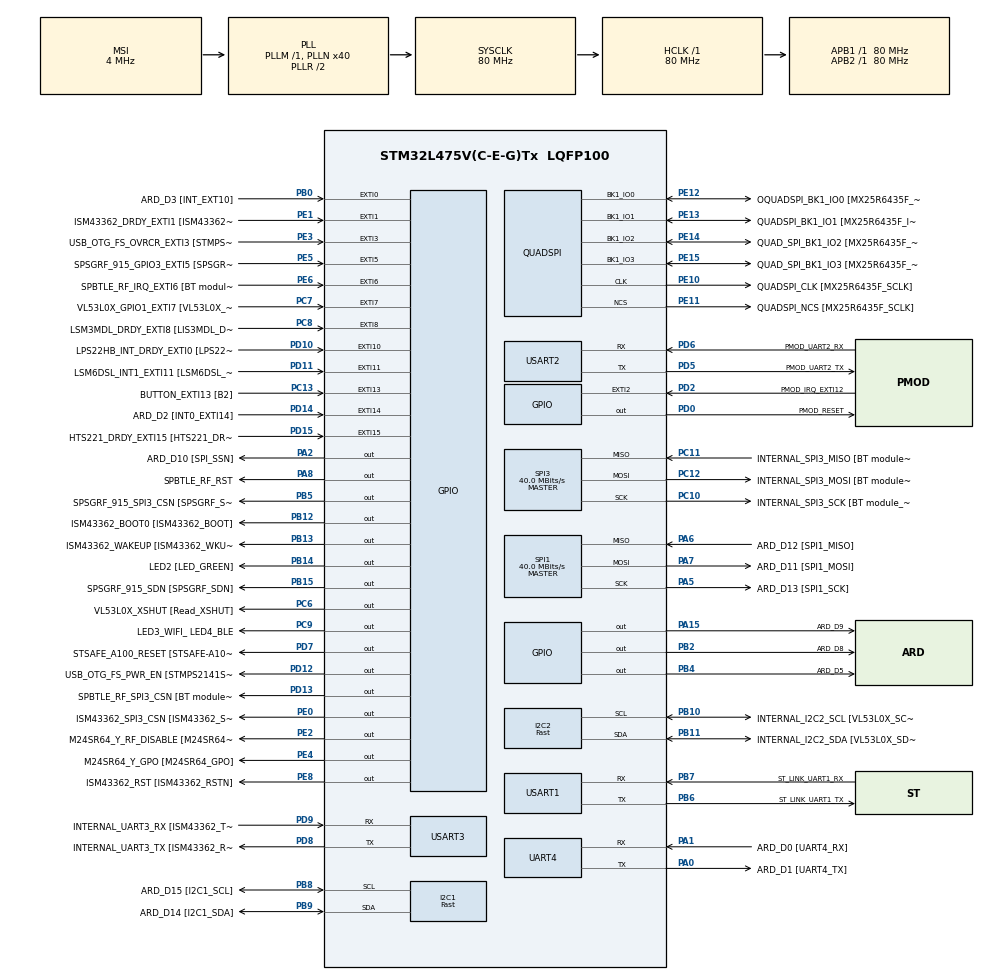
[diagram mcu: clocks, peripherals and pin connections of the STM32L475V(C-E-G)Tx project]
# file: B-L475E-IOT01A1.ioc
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PD12.GPIO_Label=USB_OTG_FS_PWR_EN [STMPS2141STR_EN]
SPI3.Direction=SPI_DIRECTION_2LINES
SPI3.VirtualType=VM_MASTER
I2C1.I2C_Speed_Mode=I2C_Fast
SPI1.VirtualType=VM_MASTER
PB10.Mode=I2C
PC12.Signal=SPI3_MOSI
PB14.GPIO_Label=LED2 [LED_GREEN]
PC6.GPIO_Label=VL53L0X_XSHUT [Read_XSHUT]
PA6.GPIO_Label=ARD_D12 [SPI1_MISO]
PB6.GPIO_Label=ST_LINK_UART1_TX
PA15\ (JTDI).Signal=GPIO_Output
PB13.Signal=GPIO_Output
PD6.GPIO_Label=PMOD_UART2_RX
PE6.GPIO_Label=SPBTLE_RF_IRQ_EXTI6 [BT module_SPI_IRQ]
RCC.SYSCLKSource=RCC_SYSCLKSOURCE_PLLCLK
SH.ADCx_IN16.0=ADC1_IN16
USART3.VirtualMode-Asynchronous=VM_ASYNC
PA14\ (JTCK-SWCLK).Signal=SYS_JTCK-SWCLK
NVIC.EXTI1_IRQn=true\:5\:0\:false\:true\:true\:1\:true\:true\:true
SPI1.Direction=SPI_DIRECTION_2LINES
PD4.Signal=USART2_RTS
I2C2.I2C_Speed_Mode=I2C_Fast
RCC.APB2TimFreq_Value=80000000
PB6.Signal=USART1_TX
PC7.Signal=GPXTI7
PB6.Mode=Asynchronous
SPI1.CalculateBaudRate=40.0 MBits/s
PC3.Signal=ADCx_IN4
PD0.Signal=GPIO_Output
PD8.Signal=USART3_TX
PE5.Signal=GPXTI5
PE1.Signal=GPXTI1
NVIC.EXTI15_10_IRQn=true\:5\:0\:false\:false\:true\:true\:true\:true
PB2.Signal=GPIO_Output
PD1.GPIO_Label=PMOD_SPI2_SCK
PB12.GPIO_Label=ISM43362_BOOT0 [ISM43362_BOOT]
PC4.GPIO_Label=ARD_A1 [ADC]
PE9.Signal=S_CKOUTDFSDM1
PB1.GPIO_Label=ARD_D6 [ADC1_IN6]
PE4.GPIO_Label=M24SR64_Y_GPO [M24SR64_GPO]
PA0.Mode=Asynchronous
PE2.Signal=GPIO_Output
PA8.Signal=GPIO_Output
PE13.Mode=Single Bank
PE10.Signal=QUADSPI_CLK
PA0.Signal=UART4_TX
Mcu.Package=LQFP100
PB9.Signal=I2C1_SDA
PB1.Signal=ADCx_IN16
NVIC.TimeBase=TIM1_TRG_COM_TIM17_IRQn
SPI3.Mode=SPI_MODE_MASTER
SH.ADCx_IN14.0=ADC1_IN14
PD12.Signal=GPIO_Output
NVIC.TimeBaseIP=TIM17
PA10.Signal=USB_OTG_FS_ID
PE12.GPIO_Label=OQUADSPI_BK1_IO0 [MX25R6435F_IO0]
PC11.Mode=Full_Duplex_Master
SH.ADCx_IN9.0=ADC1_IN9
RCC.APB1TimFreq_Value=80000000
PA13\ (JTMS-SWDIO).Signal=SYS_JTMS-SWDIO
PE10.GPIO_Label=QUADSPI_CLK [MX25R6435F_SCLK]
PA4.GPIO_Label=ARD_D7
PD15.Signal=GPXTI15
NVIC.UART4_IRQn=true\:5\:0\:false\:false\:true\:true\:true\:true
PA5.Mode=Full_Duplex_Master
PE12.Mode=Single Bank
NVIC.QUADSPI_IRQn=true\:5\:0\:false\:false\:true\:true\:true\:true
FREERTOS.Tasks01=defaultTask,24,128,StartDefaultTask,Default,NULL,Dynamic,NULL,NULL;App_Main_Task,40,256,APP_Main_Task,Default,NULL,Dynamic,NULL,NULL;App_Drv_Main_Ta,48,256,App_Drv_Main_Task,Default,NULL,Dynamic,NULL,NULL
PD9.GPIO_Label=INTERNAL_UART3_RX [ISM43362_TX]
VP_SYS_VS_tim17.Mode=TIM17
PA9.GPIO_Label=USB_OTG_FS_VBUS [STMPS2141STR_OUT]
PC13.Signal=GPXTI13
PD3.Signal=USART2_CTS
PC6.Signal=GPIO_Output
PE10.Mode=Single Bank
PC2.Signal=ADCx_IN3
PB11.GPIO_Label=INTERNAL_I2C2_SDA [VL53L0X_SDA]
PD7.Signal=GPIO_Output
PD1.Signal=SPI2_SCK
PA11.GPIO_Label=USB_OTG_FS_DM
PC0.Signal=ADCx_IN1
PD6.Mode=Asynchronous
PD10.Signal=GPXTI10
PB8.GPIO_Label=ARD_D15 [I2C1_SCL]
PA8.GPIO_Label=SPBTLE_RF_RST
PB11.Mode=I2C
PE8.GPIO_Label=ISM43362_RST [ISM43362_RSTN]
PA9.Signal=USB_OTG_FS_VBUS
I2C1.Timing=0x00702991
NVIC.I2C2_ER_IRQn=true\:5\:0\:false\:false\:true\:true\:true\:true
PE9.GPIO_Label=DFSDM1_CKOUT [MP34DT01_CLK]
PD8.Mode=Asynchronous
PB10.Signal=I2C2_SCL
PB14.Signal=GPIO_Output
PA5.Signal=SPI1_SCK
PC12.Mode=Full_Duplex_Master
PE1.GPIO_Label=ISM43362_DRDY_EXTI1 [ISM43362_DATARDY]
NVIC.SPI1_IRQn=true\:5\:0\:false\:false\:true\:true\:true\:true
PA1.Mode=Asynchronous
PE14.Signal=QUADSPI_BK1_IO2
PE15.Signal=QUADSPI_BK1_IO3
PB15.GPIO_Label=SPSGRF_915_SDN [SPSGRF_SDN]
PE8.Signal=GPIO_Output
SPI1.Mode=SPI_MODE_MASTER
PA1.GPIO_Label=ARD_D0 [UART4_RX]
SH.ADCx_IN4.0=ADC1_IN4
PC7.GPIO_Label=VL53L0X_GPIO1_EXTI7 [VL53L0X_GPIO1]
PA13\ (JTMS-SWDIO).Mode=Serial_Wire
PA4.Signal=ADCx_IN9
PB5.Signal=GPIO_Output
PE13.GPIO_Label=QUADSPI_BK1_IO1 [MX25R6435F_IO1]
PA5.GPIO_Label=ARD_D13 [SPI1_SCK]
PD11.Signal=GPXTI11
PE5.GPIO_Label=SPSGRF_915_GPIO3_EXTI5 [SPSGRF_GPIO_3]
PC12.GPIO_Label=INTERNAL_SPI3_MOSI [BT module_SPI_MOSI] [ISM43362_MOSI]
PA11.Signal=USB_OTG_FS_DM
ProjectManager.HeapSize=0x1000
NVIC.PriorityGroup=NVIC_PRIORITYGROUP_4
PB8.Mode=I2C
PE3.Signal=GPXTI3
PC3.GPIO_Label=ARD_A2 [ADC]
PB4\ (NJTRST).GPIO_Label=ARD_D5
PD2.Signal=GPXTI2
PB0.Signal=GPXTI0
PC1.Signal=ADCx_IN2
PD2.GPIO_Label=PMOD_IRQ_EXTI12
PE15.Mode=Single Bank
Mcu.Family=STM32L4
NVIC.USART3_IRQn=true\:5\:0\:false\:false\:true\:true\:true\:true
PA6.Mode=Full_Duplex_Master
RCC.CortexFreq_Value=80000000
PE11.GPIO_Label=QUADSPI_NCS [MX25R6435F_SCLK]
SH.ADCx_IN2.0=ADC1_IN2
PC10.Signal=SPI3_SCK
I2C2.Timing=0x00702991
PA0.GPIO_Label=ARD_D1 [UART4_TX]
PC0.GPIO_Label=ARD_A5 [ADC]
PD0.GPIO_Label=PMOD_RESET
PB0.GPIO_Label=ARD_D3 [INT_EXT10]
PC13.GPIO_Label=BUTTON_EXTI13 [B2]
PB13.GPIO_Label=ISM43362_WAKEUP [ISM43362_WKUP]
PB11.Signal=I2C2_SDA
PB15.Signal=GPIO_Output
PD9.Mode=Asynchronous
ProjectManager.StackSize=0x1000
PB3\ (JTDO-TRACESWO).Signal=SYS_JTDO-SWO
VP_FREERTOS_VS_CMSIS_V2.Mode=CMSIS_V2
PD13.Signal=GPIO_Output
PA12.Signal=USB_OTG_FS_DP
PE11.Mode=Single Bank
PD11.GPIO_Label=LSM6DSL_INT1_EXTI11 [LSM6DSL_INT1]
RCC.HCLKFreq_Value=80000000
SH.ADCx_IN3.0=ADC1_IN3
PB5.PinState=GPIO_PIN_SET
RCC.AHBFreq_Value=80000000
PD5.Mode=Asynchronous
RCC.HSE_VALUE=8000000
USART2.VirtualMode-Asynchronous=VM_ASYNC
NVIC.TIM1_TRG_COM_TIM17_IRQn=true\:0\:0\:false\:false\:true\:false\:false\:true
PE13.Signal=QUADSPI_BK1_IO1
PC11.GPIO_Label=INTERNAL_SPI3_MISO [BT module_SPI_MISO] [ISM43362_MISO]
PA10.GPIO_Label=USB_OTG_FS_ID
PB7.Signal=USART1_RX
PE4.Signal=GPIO_Output
PD7.GPIO_Label=STSAFE_A100_RESET [STSAFE-A100_RESET]
PB7.GPIO_Label=ST_LINK_UART1_RX
PD13.GPIO_Label=SPBTLE_RF_SPI3_CSN [BT module_SPI_CS]
PA6.Signal=SPI1_MISO
PD5.GPIO_Label=PMOD_UART2_TX
PA2.GPIO_Label=ARD_D10 [SPI_SSN]
NVIC.SPI3_IRQn=true\:5\:0\:false\:false\:true\:true\:true\:true
PE0.GPIO_Label=ISM43362_SPI3_CSN [ISM43362_SSN]
SH.ADCx_IN1.0=ADC1_IN1
PB5.GPIO_Label=SPSGRF_915_SPI3_CSN [SPSGRF_SPI_CS]
PC5.Signal=ADCx_IN14
PD3.GPIO_Label=PMOD_UART2_CTS
PE7.Signal=S_DATAIN2DFSDM1
PD6.Signal=USART2_RX
PE2.GPIO_Label=M24SR64_Y_RF_DISABLE [M24SR64_RFDIS]
PC2.GPIO_Label=ARD_A3 [ADC]
RCC.PLLSAI1N=16
PA3.Signal=S_TIM2_CH4
RCC.MSI_VALUE=4000000
PA14\ (JTCK-SWCLK).Mode=Serial_Wire
SH.ADCx_IN13.0=ADC1_IN13
PD15.GPIO_Label=HTS221_DRDY_EXTI15 [HTS221_DRDY]
PA7.Mode=Full_Duplex_Master
PB9.GPIO_Label=ARD_D14 [I2C1_SDA]
PC10.GPIO_Label=INTERNAL_SPI3_SCK [BT module_SPI_SCLK] [ISM43362_SCK]
PC9.GPIO_Label=LED3_WIFI_ LED4_BLE
PC11.Signal=SPI3_MISO
PC8.Signal=GPXTI8
PC4.Signal=ADCx_IN13
PC10.Mode=Full_Duplex_Master
SH.S_DATAIN2DFSDM1.0=DFSDM1_DATIN2
PE14.GPIO_Label=QUAD_SPI_BK1_IO2 [MX25R6435F_IO2]
PC15-OSC32_OUT\ (PC15).Signal=RCC_OSC32_OUT
PD9.Signal=USART3_RX
PD5.Signal=USART2_TX
PA14\ (JTCK-SWCLK).GPIO_Label=SYS_JTCK_SWCLK
PB3\ (JTDO-TRACESWO).GPIO_Label=SYS_JTD0_SWO
VP_RNG_VS_RNG.Mode=RNG_Activate
NVIC.USART2_IRQn=true\:5\:0\:false\:false\:true\:true\:true\:true
PA12.GPIO_Label=USB_OTG_FS_DP
PD8.GPIO_Label=INTERNAL_UART3_TX [ISM43362_RX]
PC8.GPIO_Label=LSM3MDL_DRDY_EXTI8 [LIS3MDL_DRDY]
USART1.VirtualMode-Asynchronous=VM_ASYNC
PE0.PinState=GPIO_PIN_SET
PE15.GPIO_Label=QUAD_SPI_BK1_IO3 [MX25R6435F_IO3]
ProjectManager.TargetToolchain=STM32CubeIDE
PB10.GPIO_Label=INTERNAL_I2C2_SCL [VL53L0X_SCL]
PB9.Mode=I2C
RCC.USBFreq_Value=32000000
PD10.GPIO_Label=LPS22HB_INT_DRDY_EXTI0 [LPS22HB_INT_DRDY] 
PE11.Signal=QUADSPI_NCS
RCC.LSE_VALUE=32768
PA1.Signal=UART4_RX
board=B-L475E-IOT01A1
RCC.VCOOutputFreq_Value=160000000
RCC.APB2Freq_Value=80000000
SPI3.CalculateBaudRate=40.0 MBits/s
PA13\ (JTMS-SWDIO).GPIO_Label=SYS_JTMS_SWDIO
PD4.GPIO_Label=PMOD_UART2_RTS
PE14.Mode=Single Bank
SH.S_CKOUTDFSDM1.0=DFSDM1_CKOUT
RCC.ADCFreq_Value=32000000
PC1.GPIO_Label=ARD_A4 [ADC]
PD14.GPIO_Label=ARD_D2 [INT0_EXTI14]
PE6.Signal=GPXTI6
PA15\ (JTDI).GPIO_Label=ARD_D9
Mcu.Name=STM32L475V(C-E-G)Tx
PE0.Signal=GPIO_Output
PE7.GPIO_Label=DFSDM1_DATIN2 [MP34DT01_DOUT]
PE12.Signal=QUADSPI_BK1_IO0
PA2.Signal=GPIO_Output
PD14.Signal=GPXTI14
RCC.SYSCLKFreq_VALUE=80000000
PA7.GPIO_Label=ARD_D11 [SPI1_MOSI]
PC13.GPIO_ModeDefaultEXTI=GPIO_MODE_IT_FALLING
PC5.GPIO_Label=ARD_A0 [ADC]
PC14-OSC32_IN\ (PC14).Signal=RCC_OSC32_IN
PB7.Mode=Asynchronous
NVIC.EXTI9_5_IRQn=true\:5\:0\:false\:false\:true\:true\:true\:true
PB2.GPIO_Label=ARD_D8
SH.S_TIM2_CH4.0=TIM2_CH4
NVIC.I2C2_EV_IRQn=true\:5\:0\:false\:false\:true\:true\:true\:true
RCC.HSI_VALUE=16000000
RCC.PLLN=40
PB8.Signal=I2C1_SCL
PE3.GPIO_Label=USB_OTG_FS_OVRCR_EXTI3 [STMPS2141STR_FAULT]
PC9.Signal=GPIO_Output
PD13.PinState=GPIO_PIN_SET
RCC.APB1Freq_Value=80000000
PB12.Signal=GPIO_Output
PA3.GPIO_Label=ARD_D4
PA7.Signal=SPI1_MOSI
PB4\ (NJTRST).Signal=GPIO_Output

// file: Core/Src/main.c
/* USER CODE BEGIN Header */
/**
  ******************************************************************************
  * @file           : main.c
  * @brief          : Main program body
  ******************************************************************************
  * @attention
  *
  * <h2><center>&copy; Copyright (c) 2021 STMicroelectronics.
  * All rights reserved.</center></h2>
  *
  * This software component is licensed by ST under BSD 3-Clause license,
  * the "License"; You may not use this file except in compliance with the
  * License. You may obtain a copy of the License at:
  *                        opensource.org/licenses/BSD-3-Clause
  *
  ******************************************************************************
  */
/* USER CODE END Header */
#include "main.h"
#include "cmsis_os.h"

/* USER CODE BEGIN Includes */
#include "APP/app_main.h"

/* USER CODE END Includes */

I2C_HandleTypeDef hi2c1;
I2C_HandleTypeDef hi2c2;

QSPI_HandleTypeDef hqspi;

RNG_HandleTypeDef hrng;

SPI_HandleTypeDef hspi1;
SPI_HandleTypeDef hspi3;

UART_HandleTypeDef huart4;
UART_HandleTypeDef huart1;
UART_HandleTypeDef huart2;
UART_HandleTypeDef huart3;

/* Definitions for defaultTask */
osThreadId_t defaultTaskHandle;
const osThreadAttr_t defaultTask_attributes = {
  .name = "defaultTask",
  .stack_size = 128 * 4,
  .priority = (osPriority_t) osPriorityNormal,
};
/* Definitions for App_Main_Task */
osThreadId_t App_Main_TaskHandle;
const osThreadAttr_t App_Main_Task_attributes = {
  .name = "App_Main_Task",
  .stack_size = 2048,
  .priority = (osPriority_t) osPriorityHigh,
};
/* Definitions for App_Drv_Main_Ta */
osThreadId_t App_Drv_Main_TaHandle;
const osThreadAttr_t App_Drv_Main_Ta_attributes = {
  .name = "App_Drv_Main_Ta",
  .stack_size = 256 * 4,
  .priority = (osPriority_t) osPriorityRealtime,
};
/* USER CODE BEGIN PV */

#if 0
osThreadId_t App_Main_Proc_TaskHandle;
const osThreadAttr_t App_Main_Proc_Task_attributes = {
  .name = "App Main Proc Task",
  .stack_size = 512 * 4,
  .priority = (osPriority_t) osPriorityHigh,
};
#endif

/* USER CODE END PV */

void SystemClock_Config(void);
static void MX_GPIO_Init(void);
static void MX_RNG_Init(void);
static void MX_I2C2_Init(void);
static void MX_QUADSPI_Init(void);
static void MX_SPI1_Init(void);
static void MX_SPI3_Init(void);
static void MX_UART4_Init(void);
static void MX_USART1_UART_Init(void);
static void MX_USART2_UART_Init(void);
static void MX_USART3_UART_Init(void);
static void MX_I2C1_Init(void);
void StartDefaultTask(void *argument);
void APP_Main_Task(void *argument);
void App_Drv_Main_Task(void *argument);

static void MX_NVIC_Init(void);

int main(void)
{

  /* MCU Configuration--------------------------------------------------------*/

  /* Reset of all peripherals, Initializes the Flash interface and the Systick. */
  HAL_Init();

  /* Configure the system clock */
  SystemClock_Config();

  /* Initialize all configured peripherals */
  MX_GPIO_Init();
  MX_RNG_Init();
  MX_I2C2_Init();
  MX_QUADSPI_Init();
  MX_SPI1_Init();
  MX_SPI3_Init();
  MX_UART4_Init();
  MX_USART1_UART_Init();
  MX_USART2_UART_Init();
  MX_USART3_UART_Init();
  MX_I2C1_Init();

  /* Initialize interrupts */
  MX_NVIC_Init();
  /* USER CODE BEGIN 2 */

  APP_BSP_Init();
  APP_Init();

  /* USER CODE END 2 */

  /* Init scheduler */
  osKernelInitialize();

  /* Create the thread(s) */
  /* creation of defaultTask */
  defaultTaskHandle = osThreadNew(StartDefaultTask, NULL, &defaultTask_attributes);

  /* creation of App_Main_Task */
  App_Main_TaskHandle = osThreadNew(APP_Main_Task, NULL, &App_Main_Task_attributes);

  /* creation of App_Drv_Main_Ta */
  App_Drv_Main_TaHandle = osThreadNew(App_Drv_Main_Task, NULL, &App_Drv_Main_Ta_attributes);

  /* USER CODE BEGIN RTOS_THREADS */
  /* add threads, ... */

  // APP Main Proc Task Create
  // App_Main_Proc_TaskHandle = osThreadNew(APP_Main_Proc_Task, NULL, &App_Main_Proc_Task_attributes);

  /* USER CODE END RTOS_THREADS */

  /* Start scheduler */
  osKernelStart();

  /* We should never get here as control is now taken by the scheduler */
  /* Infinite loop */
  while (1)
  {

  }
}

void SystemClock_Config(void)
{
  RCC_OscInitTypeDef RCC_OscInitStruct = {0};
  RCC_ClkInitTypeDef RCC_ClkInitStruct = {0};
  RCC_PeriphCLKInitTypeDef PeriphClkInit = {0};

  /** Initializes the RCC Oscillators according to the specified parameters
  * in the RCC_OscInitTypeDef structure.
  */
  RCC_OscInitStruct.OscillatorType = RCC_OSCILLATORTYPE_MSI;
  RCC_OscInitStruct.MSIState = RCC_MSI_ON;
  RCC_OscInitStruct.MSICalibrationValue = 0;
  RCC_OscInitStruct.MSIClockRange = RCC_MSIRANGE_6;
  RCC_OscInitStruct.PLL.PLLState = RCC_PLL_ON;
  RCC_OscInitStruct.PLL.PLLSource = RCC_PLLSOURCE_MSI;
  RCC_OscInitStruct.PLL.PLLM = 1;
  RCC_OscInitStruct.PLL.PLLN = 40;
  RCC_OscInitStruct.PLL.PLLP = RCC_PLLP_DIV7;
  RCC_OscInitStruct.PLL.PLLQ = RCC_PLLQ_DIV2;
  RCC_OscInitStruct.PLL.PLLR = RCC_PLLR_DIV2;
  if (HAL_RCC_OscConfig(&RCC_OscInitStruct) != HAL_OK)
  {
    Error_Handler();
  }
  /** Initializes the CPU, AHB and APB buses clocks
  */
  RCC_ClkInitStruct.ClockType = RCC_CLOCKTYPE_HCLK|RCC_CLOCKTYPE_SYSCLK
                              |RCC_CLOCKTYPE_PCLK1|RCC_CLOCKTYPE_PCLK2;
  RCC_ClkInitStruct.SYSCLKSource = RCC_SYSCLKSOURCE_PLLCLK;
  RCC_ClkInitStruct.AHBCLKDivider = RCC_SYSCLK_DIV1;
  RCC_ClkInitStruct.APB1CLKDivider = RCC_HCLK_DIV1;
  RCC_ClkInitStruct.APB2CLKDivider = RCC_HCLK_DIV1;

  if (HAL_RCC_ClockConfig(&RCC_ClkInitStruct, FLASH_LATENCY_4) != HAL_OK)
  {
    Error_Handler();
  }
  PeriphClkInit.PeriphClockSelection = RCC_PERIPHCLK_USART1|RCC_PERIPHCLK_USART2
                              |RCC_PERIPHCLK_USART3|RCC_PERIPHCLK_UART4
                              |RCC_PERIPHCLK_I2C1|RCC_PERIPHCLK_I2C2
                              |RCC_PERIPHCLK_RNG;
  PeriphClkInit.Usart1ClockSelection = RCC_USART1CLKSOURCE_PCLK2;
  PeriphClkInit.Usart2ClockSelection = RCC_USART2CLKSOURCE_PCLK1;
  PeriphClkInit.Usart3ClockSelection = RCC_USART3CLKSOURCE_PCLK1;
  PeriphClkInit.Uart4ClockSelection = RCC_UART4CLKSOURCE_PCLK1;
  PeriphClkInit.I2c1ClockSelection = RCC_I2C1CLKSOURCE_PCLK1;
  PeriphClkInit.I2c2ClockSelection = RCC_I2C2CLKSOURCE_PCLK1;
  PeriphClkInit.RngClockSelection = RCC_RNGCLKSOURCE_PLLSAI1;
  PeriphClkInit.PLLSAI1.PLLSAI1Source = RCC_PLLSOURCE_MSI;
  PeriphClkInit.PLLSAI1.PLLSAI1M = 1;
  PeriphClkInit.PLLSAI1.PLLSAI1N = 16;
  PeriphClkInit.PLLSAI1.PLLSAI1P = RCC_PLLP_DIV7;
  PeriphClkInit.PLLSAI1.PLLSAI1Q = RCC_PLLQ_DIV2;
  PeriphClkInit.PLLSAI1.PLLSAI1R = RCC_PLLR_DIV2;
  PeriphClkInit.PLLSAI1.PLLSAI1ClockOut = RCC_PLLSAI1_48M2CLK;
  if (HAL_RCCEx_PeriphCLKConfig(&PeriphClkInit) != HAL_OK)
  {
    Error_Handler();
  }
  /** Configure the main internal regulator output voltage
  */
  if (HAL_PWREx_ControlVoltageScaling(PWR_REGULATOR_VOLTAGE_SCALE1) != HAL_OK)
  {
    Error_Handler();
  }
}

/**
  * @brief NVIC Configuration.
  * @retval None
  */
static void MX_NVIC_Init(void)
{
  /* EXTI1_IRQn interrupt configuration */
  HAL_NVIC_SetPriority(EXTI1_IRQn, 5, 0);
  HAL_NVIC_EnableIRQ(EXTI1_IRQn);
}

static void MX_I2C1_Init(void)
{

  hi2c1.Instance = I2C1;
  hi2c1.Init.Timing = 0x00702991;
  hi2c1.Init.OwnAddress1 = 0;
  hi2c1.Init.AddressingMode = I2C_ADDRESSINGMODE_7BIT;
  hi2c1.Init.DualAddressMode = I2C_DUALADDRESS_DISABLE;
  hi2c1.Init.OwnAddress2 = 0;
  hi2c1.Init.OwnAddress2Masks = I2C_OA2_NOMASK;
  hi2c1.Init.GeneralCallMode = I2C_GENERALCALL_DISABLE;
  hi2c1.Init.NoStretchMode = I2C_NOSTRETCH_DISABLE;
  if (HAL_I2C_Init(&hi2c1) != HAL_OK)
  {
    Error_Handler();
  }
  /** Configure Analogue filter
  */
  if (HAL_I2CEx_ConfigAnalogFilter(&hi2c1, I2C_ANALOGFILTER_ENABLE) != HAL_OK)
  {
    Error_Handler();
  }
  /** Configure Digital filter
  */
  if (HAL_I2CEx_ConfigDigitalFilter(&hi2c1, 0) != HAL_OK)
  {
    Error_Handler();
  }

}

static void MX_I2C2_Init(void)
{

  hi2c2.Instance = I2C2;
  hi2c2.Init.Timing = 0x00702991;
  hi2c2.Init.OwnAddress1 = 0;
  hi2c2.Init.AddressingMode = I2C_ADDRESSINGMODE_7BIT;
  hi2c2.Init.DualAddressMode = I2C_DUALADDRESS_DISABLE;
  hi2c2.Init.OwnAddress2 = 0;
  hi2c2.Init.OwnAddress2Masks = I2C_OA2_NOMASK;
  hi2c2.Init.GeneralCallMode = I2C_GENERALCALL_DISABLE;
  hi2c2.Init.NoStretchMode = I2C_NOSTRETCH_DISABLE;
  if (HAL_I2C_Init(&hi2c2) != HAL_OK)
  {
    Error_Handler();
  }
  /** Configure Analogue filter
  */
  if (HAL_I2CEx_ConfigAnalogFilter(&hi2c2, I2C_ANALOGFILTER_ENABLE) != HAL_OK)
  {
    Error_Handler();
  }
  /** Configure Digital filter
  */
  if (HAL_I2CEx_ConfigDigitalFilter(&hi2c2, 0) != HAL_OK)
  {
    Error_Handler();
  }

}

static void MX_QUADSPI_Init(void)
{

  /* QUADSPI parameter configuration*/
  hqspi.Instance = QUADSPI;
  hqspi.Init.ClockPrescaler = 255;
  hqspi.Init.FifoThreshold = 1;
  hqspi.Init.SampleShifting = QSPI_SAMPLE_SHIFTING_NONE;
  hqspi.Init.FlashSize = 1;
  hqspi.Init.ChipSelectHighTime = QSPI_CS_HIGH_TIME_1_CYCLE;
  hqspi.Init.ClockMode = QSPI_CLOCK_MODE_0;
  if (HAL_QSPI_Init(&hqspi) != HAL_OK)
  {
    Error_Handler();
  }

}

static void MX_RNG_Init(void)
{

  hrng.Instance = RNG;
  if (HAL_RNG_Init(&hrng) != HAL_OK)
  {
    Error_Handler();
  }

}

static void MX_SPI1_Init(void)
{

  /* SPI1 parameter configuration*/
  hspi1.Instance = SPI1;
  hspi1.Init.Mode = SPI_MODE_MASTER;
  hspi1.Init.Direction = SPI_DIRECTION_2LINES;
  hspi1.Init.DataSize = SPI_DATASIZE_4BIT;
  hspi1.Init.CLKPolarity = SPI_POLARITY_LOW;
  hspi1.Init.CLKPhase = SPI_PHASE_1EDGE;
  hspi1.Init.NSS = SPI_NSS_SOFT;
  hspi1.Init.BaudRatePrescaler = SPI_BAUDRATEPRESCALER_2;
  hspi1.Init.FirstBit = SPI_FIRSTBIT_MSB;
  hspi1.Init.TIMode = SPI_TIMODE_DISABLE;
  hspi1.Init.CRCCalculation = SPI_CRCCALCULATION_DISABLE;
  hspi1.Init.CRCPolynomial = 7;
  hspi1.Init.CRCLength = SPI_CRC_LENGTH_DATASIZE;
  hspi1.Init.NSSPMode = SPI_NSS_PULSE_ENABLE;
  if (HAL_SPI_Init(&hspi1) != HAL_OK)
  {
    Error_Handler();
  }

}

static void MX_SPI3_Init(void)
{

  /* SPI3 parameter configuration*/
  hspi3.Instance = SPI3;
  hspi3.Init.Mode = SPI_MODE_MASTER;
  hspi3.Init.Direction = SPI_DIRECTION_2LINES;
  hspi3.Init.DataSize = SPI_DATASIZE_4BIT;
  hspi3.Init.CLKPolarity = SPI_POLARITY_LOW;
  hspi3.Init.CLKPhase = SPI_PHASE_1EDGE;
  hspi3.Init.NSS = SPI_NSS_SOFT;
  hspi3.Init.BaudRatePrescaler = SPI_BAUDRATEPRESCALER_2;
  hspi3.Init.FirstBit = SPI_FIRSTBIT_MSB;
  hspi3.Init.TIMode = SPI_TIMODE_DISABLE;
  hspi3.Init.CRCCalculation = SPI_CRCCALCULATION_DISABLE;
  hspi3.Init.CRCPolynomial = 7;
  hspi3.Init.CRCLength = SPI_CRC_LENGTH_DATASIZE;
  hspi3.Init.NSSPMode = SPI_NSS_PULSE_ENABLE;
  if (HAL_SPI_Init(&hspi3) != HAL_OK)
  {
    Error_Handler();
  }

}

static void MX_UART4_Init(void)
{

  huart4.Instance = UART4;
  huart4.Init.BaudRate = 115200;
  huart4.Init.WordLength = UART_WORDLENGTH_8B;
  huart4.Init.StopBits = UART_STOPBITS_1;
  huart4.Init.Parity = UART_PARITY_NONE;
  huart4.Init.Mode = UART_MODE_TX_RX;
  huart4.Init.HwFlowCtl = UART_HWCONTROL_NONE;
  huart4.Init.OverSampling = UART_OVERSAMPLING_16;
  huart4.Init.OneBitSampling = UART_ONE_BIT_SAMPLE_DISABLE;
  huart4.AdvancedInit.AdvFeatureInit = UART_ADVFEATURE_NO_INIT;
  if (HAL_UART_Init(&huart4) != HAL_OK)
  {
    Error_Handler();
  }

}

static void MX_USART1_UART_Init(void)
{

  huart1.Instance = USART1;
  huart1.Init.BaudRate = 115200;
  huart1.Init.WordLength = UART_WORDLENGTH_8B;
  huart1.Init.StopBits = UART_STOPBITS_1;
  huart1.Init.Parity = UART_PARITY_NONE;
  huart1.Init.Mode = UART_MODE_TX_RX;
  huart1.Init.HwFlowCtl = UART_HWCONTROL_NONE;
  huart1.Init.OverSampling = UART_OVERSAMPLING_16;
  huart1.Init.OneBitSampling = UART_ONE_BIT_SAMPLE_DISABLE;
  huart1.AdvancedInit.AdvFeatureInit = UART_ADVFEATURE_NO_INIT;
  if (HAL_UART_Init(&huart1) != HAL_OK)
  {
    Error_Handler();
  }

}

static void MX_USART2_UART_Init(void)
{

  huart2.Instance = USART2;
  huart2.Init.BaudRate = 115200;
  huart2.Init.WordLength = UART_WORDLENGTH_8B;
  huart2.Init.StopBits = UART_STOPBITS_1;
  huart2.Init.Parity = UART_PARITY_NONE;
  huart2.Init.Mode = UART_MODE_TX_RX;
  huart2.Init.HwFlowCtl = UART_HWCONTROL_NONE;
  huart2.Init.OverSampling = UART_OVERSAMPLING_16;
  huart2.Init.OneBitSampling = UART_ONE_BIT_SAMPLE_DISABLE;
  huart2.AdvancedInit.AdvFeatureInit = UART_ADVFEATURE_NO_INIT;
  if (HAL_UART_Init(&huart2) != HAL_OK)
  {
    Error_Handler();
  }

}

static void MX_USART3_UART_Init(void)
{

  huart3.Instance = USART3;
  huart3.Init.BaudRate = 115200;
  huart3.Init.WordLength = UART_WORDLENGTH_8B;
  huart3.Init.StopBits = UART_STOPBITS_1;
  huart3.Init.Parity = UART_PARITY_NONE;
  huart3.Init.Mode = UART_MODE_TX_RX;
  huart3.Init.HwFlowCtl = UART_HWCONTROL_NONE;
  huart3.Init.OverSampling = UART_OVERSAMPLING_16;
  huart3.Init.OneBitSampling = UART_ONE_BIT_SAMPLE_DISABLE;
  huart3.AdvancedInit.AdvFeatureInit = UART_ADVFEATURE_NO_INIT;
  if (HAL_UART_Init(&huart3) != HAL_OK)
  {
    Error_Handler();
  }

}

static void MX_GPIO_Init(void)
{
  GPIO_InitTypeDef GPIO_InitStruct = {0};

  /* GPIO Ports Clock Enable */
  __HAL_RCC_GPIOE_CLK_ENABLE();
  __HAL_RCC_GPIOC_CLK_ENABLE();
  __HAL_RCC_GPIOA_CLK_ENABLE();
  __HAL_RCC_GPIOB_CLK_ENABLE();
  __HAL_RCC_GPIOD_CLK_ENABLE();

  /*Configure GPIO pin Output Level */
  HAL_GPIO_WritePin(GPIOE, M24SR64_Y_RF_DISABLE_Pin|M24SR64_Y_GPO_Pin|ISM43362_RST_Pin, GPIO_PIN_RESET);

  /*Configure GPIO pin Output Level */
  HAL_GPIO_WritePin(GPIOA, ARD_D10_Pin|SPBTLE_RF_RST_Pin|ARD_D9_Pin, GPIO_PIN_RESET);

  /*Configure GPIO pin Output Level */
  HAL_GPIO_WritePin(GPIOB, ARD_D8_Pin|ISM43362_BOOT0_Pin|ISM43362_WAKEUP_Pin|LED2_Pin
                          |SPSGRF_915_SDN_Pin|ARD_D5_Pin, GPIO_PIN_RESET);

  /*Configure GPIO pin Output Level */
  HAL_GPIO_WritePin(GPIOD, USB_OTG_FS_PWR_EN_Pin|PMOD_RESET_Pin|STSAFE_A100_RESET_Pin, GPIO_PIN_RESET);

  /*Configure GPIO pin Output Level */
  HAL_GPIO_WritePin(SPBTLE_RF_SPI3_CSN_GPIO_Port, SPBTLE_RF_SPI3_CSN_Pin, GPIO_PIN_SET);

  /*Configure GPIO pin Output Level */
  HAL_GPIO_WritePin(GPIOC, VL53L0X_XSHUT_Pin|LED3_WIFI__LED4_BLE_Pin, GPIO_PIN_RESET);

  /*Configure GPIO pin Output Level */
  HAL_GPIO_WritePin(SPSGRF_915_SPI3_CSN_GPIO_Port, SPSGRF_915_SPI3_CSN_Pin, GPIO_PIN_SET);

  /*Configure GPIO pin Output Level */
  HAL_GPIO_WritePin(ISM43362_SPI3_CSN_GPIO_Port, ISM43362_SPI3_CSN_Pin, GPIO_PIN_SET);

  /*Configure GPIO pins : M24SR64_Y_RF_DISABLE_Pin M24SR64_Y_GPO_Pin ISM43362_RST_Pin ISM43362_SPI3_CSN_Pin */
  GPIO_InitStruct.Pin = M24SR64_Y_RF_DISABLE_Pin|M24SR64_Y_GPO_Pin|ISM43362_RST_Pin|ISM43362_SPI3_CSN_Pin;
  GPIO_InitStruct.Mode = GPIO_MODE_OUTPUT_PP;
  GPIO_InitStruct.Pull = GPIO_NOPULL;
  GPIO_InitStruct.Speed = GPIO_SPEED_FREQ_LOW;
  HAL_GPIO_Init(GPIOE, &GPIO_InitStruct);

  /*Configure GPIO pins : USB_OTG_FS_OVRCR_EXTI3_Pin SPSGRF_915_GPIO3_EXTI5_Pin SPBTLE_RF_IRQ_EXTI6_Pin ISM43362_DRDY_EXTI1_Pin */
  GPIO_InitStruct.Pin = USB_OTG_FS_OVRCR_EXTI3_Pin|SPSGRF_915_GPIO3_EXTI5_Pin|SPBTLE_RF_IRQ_EXTI6_Pin|ISM43362_DRDY_EXTI1_Pin;
  GPIO_InitStruct.Mode = GPIO_MODE_IT_RISING;
  GPIO_InitStruct.Pull = GPIO_NOPULL;
  HAL_GPIO_Init(GPIOE, &GPIO_InitStruct);

  /*Configure GPIO pin : BUTTON_EXTI13_Pin */
  GPIO_InitStruct.Pin = BUTTON_EXTI13_Pin;
  GPIO_InitStruct.Mode = GPIO_MODE_IT_FALLING;
  GPIO_InitStruct.Pull = GPIO_NOPULL;
  HAL_GPIO_Init(BUTTON_EXTI13_GPIO_Port, &GPIO_InitStruct);

  /*Configure GPIO pins : ARD_A5_Pin ARD_A4_Pin ARD_A3_Pin ARD_A2_Pin
                           ARD_A1_Pin ARD_A0_Pin */
  GPIO_InitStruct.Pin = ARD_A5_Pin|ARD_A4_Pin|ARD_A3_Pin|ARD_A2_Pin
                          |ARD_A1_Pin|ARD_A0_Pin;
  GPIO_InitStruct.Mode = GPIO_MODE_ANALOG_ADC_CONTROL;
  GPIO_InitStruct.Pull = GPIO_NOPULL;
  HAL_GPIO_Init(GPIOC, &GPIO_InitStruct);

  /*Configure GPIO pins : ARD_D10_Pin SPBTLE_RF_RST_Pin ARD_D9_Pin */
  GPIO_InitStruct.Pin = ARD_D10_Pin|SPBTLE_RF_RST_Pin|ARD_D9_Pin;
  GPIO_InitStruct.Mode = GPIO_MODE_OUTPUT_PP;
  GPIO_InitStruct.Pull = GPIO_NOPULL;
  GPIO_InitStruct.Speed = GPIO_SPEED_FREQ_LOW;
  HAL_GPIO_Init(GPIOA, &GPIO_InitStruct);

  /*Configure GPIO pin : ARD_D4_Pin */
  GPIO_InitStruct.Pin = ARD_D4_Pin;
  GPIO_InitStruct.Mode = GPIO_MODE_AF_PP;
  GPIO_InitStruct.Pull = GPIO_NOPULL;
  GPIO_InitStruct.Speed = GPIO_SPEED_FREQ_LOW;
  GPIO_InitStruct.Alternate = GPIO_AF1_TIM2;
  HAL_GPIO_Init(ARD_D4_GPIO_Port, &GPIO_InitStruct);

  /*Configure GPIO pin : ARD_D7_Pin */
  GPIO_InitStruct.Pin = ARD_D7_Pin;
  GPIO_InitStruct.Mode = GPIO_MODE_ANALOG_ADC_CONTROL;
  GPIO_InitStruct.Pull = GPIO_NOPULL;
  HAL_GPIO_Init(ARD_D7_GPIO_Port, &GPIO_InitStruct);

  /*Configure GPIO pin : ARD_D3_Pin */
  GPIO_InitStruct.Pin = ARD_D3_Pin;
  GPIO_InitStruct.Mode = GPIO_MODE_IT_RISING;
  GPIO_InitStruct.Pull = GPIO_NOPULL;
  HAL_GPIO_Init(ARD_D3_GPIO_Port, &GPIO_InitStruct);

  /*Configure GPIO pin : ARD_D6_Pin */
  GPIO_InitStruct.Pin = ARD_D6_Pin;
  GPIO_InitStruct.Mode = GPIO_MODE_ANALOG_ADC_CONTROL;
  GPIO_InitStruct.Pull = GPIO_NOPULL;
  HAL_GPIO_Init(ARD_D6_GPIO_Port, &GPIO_InitStruct);

  /*Configure GPIO pins : ARD_D8_Pin ISM43362_BOOT0_Pin ISM43362_WAKEUP_Pin LED2_Pin
                           SPSGRF_915_SDN_Pin ARD_D5_Pin SPSGRF_915_SPI3_CSN_Pin */
  GPIO_InitStruct.Pin = ARD_D8_Pin|ISM43362_BOOT0_Pin|ISM43362_WAKEUP_Pin|LED2_Pin
                          |SPSGRF_915_SDN_Pin|ARD_D5_Pin|SPSGRF_915_SPI3_CSN_Pin;
  GPIO_InitStruct.Mode = GPIO_MODE_OUTPUT_PP;
  GPIO_InitStruct.Pull = GPIO_NOPULL;
  GPIO_InitStruct.Speed = GPIO_SPEED_FREQ_LOW;
  HAL_GPIO_Init(GPIOB, &GPIO_InitStruct);

  /*Configure GPIO pins : DFSDM1_DATIN2_Pin DFSDM1_CKOUT_Pin */
  GPIO_InitStruct.Pin = DFSDM1_DATIN2_Pin|DFSDM1_CKOUT_Pin;
  GPIO_InitStruct.Mode = GPIO_MODE_AF_PP;
  GPIO_InitStruct.Pull = GPIO_NOPULL;
  GPIO_InitStruct.Speed = GPIO_SPEED_FREQ_LOW;
  GPIO_InitStruct.Alternate = GPIO_AF6_DFSDM1;
  HAL_GPIO_Init(GPIOE, &GPIO_InitStruct);

  /*Configure GPIO pins : LPS22HB_INT_DRDY_EXTI0_Pin LSM6DSL_INT1_EXTI11_Pin ARD_D2_Pin HTS221_DRDY_EXTI15_Pin
                           PMOD_IRQ_EXTI12_Pin */
  GPIO_InitStruct.Pin = LPS22HB_INT_DRDY_EXTI0_Pin|LSM6DSL_INT1_EXTI11_Pin|ARD_D2_Pin|HTS221_DRDY_EXTI15_Pin
                          |PMOD_IRQ_EXTI12_Pin;
  GPIO_InitStruct.Mode = GPIO_MODE_IT_RISING;
  GPIO_InitStruct.Pull = GPIO_NOPULL;
  HAL_GPIO_Init(GPIOD, &GPIO_InitStruct);

  /*Configure GPIO pins : USB_OTG_FS_PWR_EN_Pin SPBTLE_RF_SPI3_CSN_Pin PMOD_RESET_Pin STSAFE_A100_RESET_Pin */
  GPIO_InitStruct.Pin = USB_OTG_FS_PWR_EN_Pin|SPBTLE_RF_SPI3_CSN_Pin|PMOD_RESET_Pin|STSAFE_A100_RESET_Pin;
  GPIO_InitStruct.Mode = GPIO_MODE_OUTPUT_PP;
  GPIO_InitStruct.Pull = GPIO_NOPULL;
  GPIO_InitStruct.Speed = GPIO_SPEED_FREQ_LOW;
  HAL_GPIO_Init(GPIOD, &GPIO_InitStruct);

  /*Configure GPIO pins : VL53L0X_XSHUT_Pin LED3_WIFI__LED4_BLE_Pin */
  GPIO_InitStruct.Pin = VL53L0X_XSHUT_Pin|LED3_WIFI__LED4_BLE_Pin;
  GPIO_InitStruct.Mode = GPIO_MODE_OUTPUT_PP;
  GPIO_InitStruct.Pull = GPIO_NOPULL;
  GPIO_InitStruct.Speed = GPIO_SPEED_FREQ_LOW;
  HAL_GPIO_Init(GPIOC, &GPIO_InitStruct);

  /*Configure GPIO pins : VL53L0X_GPIO1_EXTI7_Pin LSM3MDL_DRDY_EXTI8_Pin */
  GPIO_InitStruct.Pin = VL53L0X_GPIO1_EXTI7_Pin|LSM3MDL_DRDY_EXTI8_Pin;
  GPIO_InitStruct.Mode = GPIO_MODE_IT_RISING;
  GPIO_InitStruct.Pull = GPIO_NOPULL;
  HAL_GPIO_Init(GPIOC, &GPIO_InitStruct);

  /*Configure GPIO pin : USB_OTG_FS_VBUS_Pin */
  GPIO_InitStruct.Pin = USB_OTG_FS_VBUS_Pin;
  GPIO_InitStruct.Mode = GPIO_MODE_INPUT;
  GPIO_InitStruct.Pull = GPIO_NOPULL;
  HAL_GPIO_Init(USB_OTG_FS_VBUS_GPIO_Port, &GPIO_InitStruct);

  /*Configure GPIO pins : USB_OTG_FS_ID_Pin USB_OTG_FS_DM_Pin USB_OTG_FS_DP_Pin */
  GPIO_InitStruct.Pin = USB_OTG_FS_ID_Pin|USB_OTG_FS_DM_Pin|USB_OTG_FS_DP_Pin;
  GPIO_InitStruct.Mode = GPIO_MODE_AF_PP;
  GPIO_InitStruct.Pull = GPIO_NOPULL;
  GPIO_InitStruct.Speed = GPIO_SPEED_FREQ_VERY_HIGH;
  GPIO_InitStruct.Alternate = GPIO_AF10_OTG_FS;
  HAL_GPIO_Init(GPIOA, &GPIO_InitStruct);

  /*Configure GPIO pin : PMOD_SPI2_SCK_Pin */
  GPIO_InitStruct.Pin = PMOD_SPI2_SCK_Pin;
  GPIO_InitStruct.Mode = GPIO_MODE_AF_PP;
  GPIO_InitStruct.Pull = GPIO_NOPULL;
  GPIO_InitStruct.Speed = GPIO_SPEED_FREQ_VERY_HIGH;
  GPIO_InitStruct.Alternate = GPIO_AF5_SPI2;
  HAL_GPIO_Init(PMOD_SPI2_SCK_GPIO_Port, &GPIO_InitStruct);

  /* EXTI interrupt init*/
  HAL_NVIC_SetPriority(EXTI9_5_IRQn, 5, 0);
  HAL_NVIC_EnableIRQ(EXTI9_5_IRQn);

  HAL_NVIC_SetPriority(EXTI15_10_IRQn, 5, 0);
  HAL_NVIC_EnableIRQ(EXTI15_10_IRQn);

}

void StartDefaultTask(void *argument)
{
  /* USER CODE BEGIN 5 */

  /* Infinite loop */
  for(;;)
  {
    // printf("Start Default Task\r\n");
    // Kill Own
    vTaskDelete(NULL);
  }
  /* USER CODE END 5 */
}

void APP_Main_Task(void *argument)
{
  /* USER CODE BEGIN APP_Main_Task */
  /* Infinite loop */
  for(;;)
  {
    // printf("App Main Task\r\n");
    APP_Main();
    osDelay(100);
  }
  /* USER CODE END APP_Main_Task */
}

void App_Drv_Main_Task(void *argument)
{
  /* USER CODE BEGIN App_Drv_Main_Task */
  /* Infinite loop */
  for(;;)
  {
    // printf("App Drv Main Task\r\n");
//    App_Drv_Main();
    osDelay(1);
  }
  /* USER CODE END App_Drv_Main_Task */
}

 /**
  * @brief  Period elapsed callback in non blocking mode
  * @note   This function is called  when TIM17 interrupt took place, inside
  * HAL_TIM_IRQHandler(). It makes a direct call to HAL_IncTick() to increment
  * a global variable "uwTick" used as application time base.
  * @param  htim : TIM handle
  * @retval None
  */
void HAL_TIM_PeriodElapsedCallback(TIM_HandleTypeDef *htim)
{
  if (htim->Instance == TIM17) {
    HAL_IncTick();
  }
}

void Error_Handler(void)
{
  __disable_irq();
  while (1)
  {
  }
}

/************************ (C) COPYRIGHT STMicroelectronics *****END OF FILE****/
